# TM4C129EKCPDT register map
Vendor: Texas Instruments; Series: TM4C; File version: 12591
CPU: CM4 r1p2, little endian, no MPU, FPU, 3 interrupt priority bits
Registers are 32-bit, read-write, no defined reset value unless marked. A register's access mark holds for its fields unless they carry their own. Offsets are from the block's base; [hi:lo] are bit positions; {n}, {i} and the like mark numbered series.

## SHAMD5 — Register map for SHAMD5 peripheral
Base 0x44034000; register names take the prefix SHAMD5
0x00 ODIGEST_A — SHA Outer Digest A
  [31:0] SHAMD5_ODIGEST_A_DATA — Digest/Key Data
0x04 ODIGEST_B — SHA Outer Digest B
  [31:0] SHAMD5_ODIGEST_B_DATA — Digest/Key Data
0x08 ODIGEST_C — SHA Outer Digest C
  [31:0] SHAMD5_ODIGEST_C_DATA — Digest/Key Data
0x0C ODIGEST_D — SHA Outer Digest D
  [31:0] SHAMD5_ODIGEST_D_DATA — Digest/Key Data
0x10 ODIGEST_E — SHA Outer Digest E
  [31:0] SHAMD5_ODIGEST_E_DATA — Digest/Key Data
0x14 ODIGEST_F — SHA Outer Digest F
  [31:0] SHAMD5_ODIGEST_F_DATA — Digest/Key Data
0x18 ODIGEST_G — SHA Outer Digest G
  [31:0] SHAMD5_ODIGEST_G_DATA — Digest/Key Data
0x1C ODIGEST_H — SHA Outer Digest H
  [31:0] SHAMD5_ODIGEST_H_DATA — Digest/Key Data
0x20 IDIGEST_A — SHA Inner Digest A
  [31:0] SHAMD5_IDIGEST_A_DATA — Digest/Key Data
0x24 IDIGEST_B — SHA Inner Digest B
  [31:0] SHAMD5_IDIGEST_B_DATA — Digest/Key Data
0x28 IDIGEST_C — SHA Inner Digest C
  [31:0] SHAMD5_IDIGEST_C_DATA — Digest/Key Data
0x2C IDIGEST_D — SHA Inner Digest D
  [31:0] SHAMD5_IDIGEST_D_DATA — Digest/Key Data
0x30 IDIGEST_E — SHA Inner Digest E
  [31:0] SHAMD5_IDIGEST_E_DATA — Digest/Key Data
0x34 IDIGEST_F — SHA Inner Digest F
  [31:0] SHAMD5_IDIGEST_F_DATA — Digest/Key Data
0x38 IDIGEST_G — SHA Inner Digest G
  [31:0] SHAMD5_IDIGEST_G_DATA — Digest/Key Data
0x3C IDIGEST_H — SHA Inner Digest H
  [31:0] SHAMD5_IDIGEST_H_DATA — Digest/Key Data
0x40 DIGEST_COUNT — SHA Digest Count
  [31:0] SHAMD5_DIGEST_COUNT — Digest Count
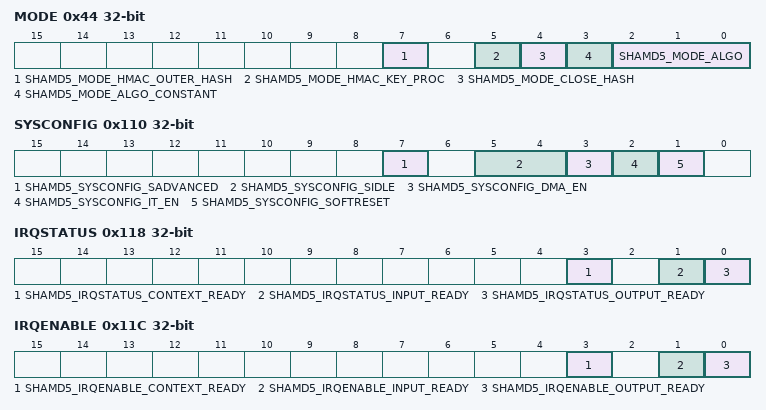
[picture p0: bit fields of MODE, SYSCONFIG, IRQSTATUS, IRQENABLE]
0x44 MODE — SHA Mode
  [7] SHAMD5_MODE_HMAC_OUTER_HASH — HMAC Outer Hash Processing Enable
  [5] SHAMD5_MODE_HMAC_KEY_PROC — HMAC Key Processing Enable
  [4] SHAMD5_MODE_CLOSE_HASH — Performs the padding, the Hash/HMAC will be 'closed' at the end of the block, as per MD5/SHA-1/SHA-2 specification
  [3] SHAMD5_MODE_ALGO_CONSTANT — The initial digest register will be overwritten with the algorithm constants for the selected algorithm when hashing and the initial digest count register will be reset to 0
  [2:0] SHAMD5_MODE_ALGO — Hash Algorithm
    0=SHAMD5_MODE_ALGO_MD5 (MD5); 2=SHAMD5_MODE_ALGO_SHA1 (SHA-1); 4=SHAMD5_MODE_ALGO_SHA224 (SHA-224); 6=SHAMD5_MODE_ALGO_SHA256 (SHA-256)
0x48 LENGTH — SHA Length
  [31:0] SHAMD5_LENGTH — Block Length/Remaining Byte Count
{0x80+4i} DATA_{i}_IN (i=0..15) — SHA Data {i} Input
  [31:0] SHAMD5_DATA_{i}_IN_DATA — Digest/Key Data
0x100 REVISION — SHA Revision
  [31:0] SHAMD5_REVISION — Revision Number
0x110 SYSCONFIG — SHA System Configuration
  [7] SHAMD5_SYSCONFIG_SADVANCED — Advanced Mode Enable
  [5:4] SHAMD5_SYSCONFIG_SIDLE — Sidle mode
    0=SHAMD5_SYSCONFIG_SIDLE_FORCE (Force-idle mode)
  [3] SHAMD5_SYSCONFIG_DMA_EN — uDMA Request Enable
  [2] SHAMD5_SYSCONFIG_IT_EN — Interrupt Enable
  [1] SHAMD5_SYSCONFIG_SOFTRESET — Soft reset
0x114 SYSSTATUS — SHA System Status
  [0] SHAMD5_SYSSTATUS_RESETDONE — Reset done status
0x118 IRQSTATUS — SHA Interrupt Status
  [3] SHAMD5_IRQSTATUS_CONTEXT_READY — Context Ready Status
  [1] SHAMD5_IRQSTATUS_INPUT_READY — Input Ready Status
  [0] SHAMD5_IRQSTATUS_OUTPUT_READY — Output Ready Status
0x11C IRQENABLE — SHA Interrupt Enable
  [3] SHAMD5_IRQENABLE_CONTEXT_READY — Mask for context ready interrupt
  [1] SHAMD5_IRQENABLE_INPUT_READY — Mask for input ready interrupt
  [0] SHAMD5_IRQENABLE_OUTPUT_READY — Mask for output ready interrupt

## DES — Register map for DES peripheral
Base 0x44038000; register names take the prefix DES
0x00 KEY3_L — DES Key 3 LSW for 192-Bit Key
  [31:0] DES_KEY3_L_KEY — Key Data
0x04 KEY3_H — DES Key 3 MSW for 192-Bit Key
  [31:0] DES_KEY3_H_KEY — Key Data
0x08 KEY2_L — DES Key 2 LSW for 128-Bit Key
  [31:0] DES_KEY2_L_KEY — Key Data
0x0C KEY2_H — DES Key 2 MSW for 128-Bit Key
  [31:0] DES_KEY2_H_KEY — Key Data
0x10 KEY1_L — DES Key 1 LSW for 64-Bit Key
  [31:0] DES_KEY1_L_KEY — Key Data
0x14 KEY1_H — DES Key 1 MSW for 64-Bit Key
  [31:0] DES_KEY1_H_KEY — Key Data
0x18 IV_L — DES Initialization Vector
  [31:0] DES_IV_L — Initialization vector for CBC, CFB modes (LSW)
0x1C IV_H — DES Initialization Vector
  [31:0] DES_IV_H — Initialization vector for CBC, CFB modes (MSW)
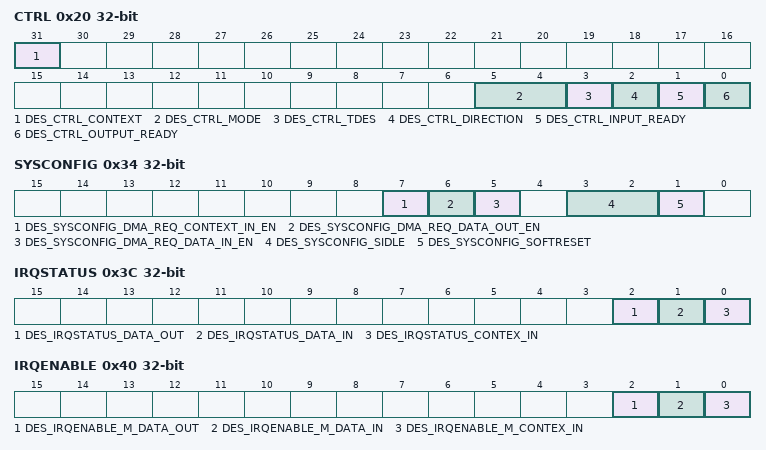
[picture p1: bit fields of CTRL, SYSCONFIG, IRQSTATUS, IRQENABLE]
0x20 CTRL — DES Control
  [31] DES_CTRL_CONTEXT — If 1, this read-only status bit indicates that the context data registers can be overwritten and the host is permitted to write the next context
  [5:4] DES_CTRL_MODE — Select CBC, ECB or CFB mode0x0: ECB mode0x1: CBC mode0x2: CFB mode0x3: reserved
  [3] DES_CTRL_TDES — Select DES or triple DES encryption/decryption
  [2] DES_CTRL_DIRECTION — Select encryption/decryption 0x0: decryption is selected0x1: Encryption is selected
  [1] DES_CTRL_INPUT_READY — When 1, ready to encrypt/decrypt data
  [0] DES_CTRL_OUTPUT_READY — When 1, Data decrypted/encrypted ready
0x24 LENGTH — DES Cryptographic Data Length
  [31:0] DES_LENGTH — Cryptographic data length in bytes for all modes
0x28 DATA_L — DES LSW Data RW
  [31:0] DES_DATA_L — Data for encryption/decryption, LSW
0x2C DATA_H — DES MSW Data RW
  [31:0] DES_DATA_H — Data for encryption/decryption, MSW
0x30 REVISION — DES Revision Number
  [31:0] DES_REVISION — Revision number
0x34 SYSCONFIG — DES System Configuration
  [7] DES_SYSCONFIG_DMA_REQ_CONTEXT_IN_EN — DMA Request Context In Enable
  [6] DES_SYSCONFIG_DMA_REQ_DATA_OUT_EN — DMA Request Data Out Enable
  [5] DES_SYSCONFIG_DMA_REQ_DATA_IN_EN — DMA Request Data In Enable
  [3:2] DES_SYSCONFIG_SIDLE — Sidle mode
    0=DES_SYSCONFIG_SIDLE_FORCE (Force-idle mode)
  [1] DES_SYSCONFIG_SOFTRESET — Soft reset
0x38 SYSSTATUS — DES System Status
  [0] DES_SYSSTATUS_RESETDONE — Reset Done
0x3C IRQSTATUS — DES Interrupt Status
  [2] DES_IRQSTATUS_DATA_OUT — This bit indicates data output interrupt is active and triggers the interrupt output
  [1] DES_IRQSTATUS_DATA_IN — This bit indicates data input interrupt is active and triggers the interrupt output
  [0] DES_IRQSTATUS_CONTEX_IN — This bit indicates context interrupt is active and triggers the interrupt output
0x40 IRQENABLE — DES Interrupt Enable
  [2] DES_IRQENABLE_M_DATA_OUT — If this bit is set to 1 the data output interrupt is enabled
  [1] DES_IRQENABLE_M_DATA_IN — If this bit is set to 1 the data input interrupt is enabled
  [0] DES_IRQENABLE_M_CONTEX_IN — If this bit is set to 1 the context interrupt is enabled
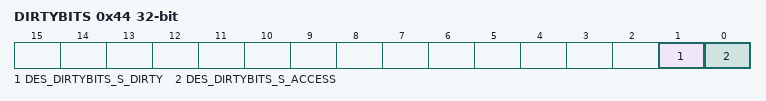
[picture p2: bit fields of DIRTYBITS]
0x44 DIRTYBITS — DES Dirty Bits
  [1] DES_DIRTYBITS_S_DIRTY — This bit is set to 1 by the module if any of the DES_* registers is written
  [0] DES_DIRTYBITS_S_ACCESS — This bit is set to 1 by the module if any of the DES_* registers is read

## Notices in the file
Software License Agreement
Texas Instruments (TI) is supplying this software for use solely and
exclusively on TI's microcontroller products. The software is owned by
TI and/or its suppliers, and is protected under applicable copyright
laws. You may not combine this software with "viral" open-source
software in order to form a larger program.
THIS SOFTWARE IS PROVIDED "AS IS" AND WITH ALL FAULTS.
NO WARRANTIES, WHETHER EXPRESS, IMPLIED OR STATUTORY, INCLUDING, BUT
NOT LIMITED TO, IMPLIED WARRANTIES OF MERCHANTABILITY AND FITNESS FOR
A PARTICULAR PURPOSE APPLY TO THIS SOFTWARE. TI SHALL NOT, UNDER ANY
CIRCUMSTANCES, BE LIABLE FOR SPECIAL, INCIDENTAL, OR CONSEQUENTIAL
DAMAGES, FOR ANY REASON WHATSOEVER.
